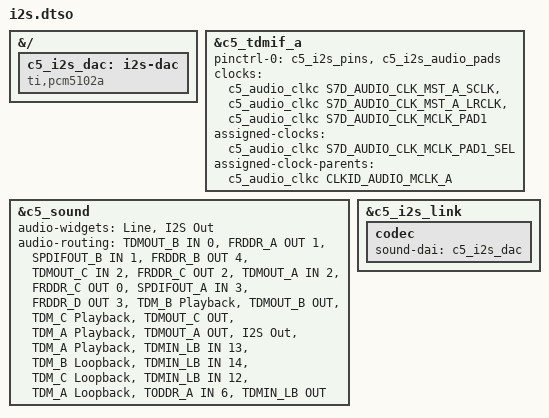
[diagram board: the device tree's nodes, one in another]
// SPDX-License-Identifier: (GPL-2.0-only OR MIT)
/* Copyright (c) 2026 Hardkernel Co., Ltd. */

/dts-v1/;
/plugin/;

#include <dt-bindings/clock/amlogic,s7d-audio-clkc.h>

&{/} {
	c5_i2s_dac: i2s-dac {
		compatible = "ti,pcm5102a";
		#sound-dai-cells = <0>;
	};
};

&c5_tdmif_a {
	pinctrl-names = "default";
	pinctrl-0 = <&c5_i2s_pins>, <&c5_i2s_audio_pads>;
	/* MCLK pad 1 (pin 7) is the master clock the DAC gets. */
	clocks = <&c5_audio_clkc S7D_AUDIO_CLK_MST_A_SCLK>,
		 <&c5_audio_clkc S7D_AUDIO_CLK_MST_A_LRCLK>,
		 <&c5_audio_clkc S7D_AUDIO_CLK_MCLK_PAD1>;
	assigned-clocks = <&c5_audio_clkc S7D_AUDIO_CLK_MCLK_PAD1_SEL>;
	assigned-clock-parents = <&c5_audio_clkc CLKID_AUDIO_MCLK_A>;
	status = "okay";
};

&c5_sound {
	/* The PCM5102A has no DAPM widgets; give TDM_A an endpoint. */
	audio-widgets = "Line", "I2S Out";
	/* hw:0,2 plays to the line out and the I2S DAC together. */
	audio-routing = "TDMOUT_B IN 0", "FRDDR_A OUT 1",
			"SPDIFOUT_B IN 1", "FRDDR_B OUT 4",
			"TDMOUT_C IN 2", "FRDDR_C OUT 2",
			"TDMOUT_A IN 2", "FRDDR_C OUT 0",
			"SPDIFOUT_A IN 3", "FRDDR_D OUT 3",
			"TDM_B Playback", "TDMOUT_B OUT",
			"TDM_C Playback", "TDMOUT_C OUT",
			"TDM_A Playback", "TDMOUT_A OUT",
			"I2S Out", "TDM_A Playback",
			"TDMIN_LB IN 13", "TDM_B Loopback",
			"TDMIN_LB IN 14", "TDM_C Loopback",
			"TDMIN_LB IN 12", "TDM_A Loopback",
			"TODDR_A IN 6", "TDMIN_LB OUT";
};

&c5_i2s_link {
	status = "okay";

	codec {
		sound-dai = <&c5_i2s_dac>;
	};
};
